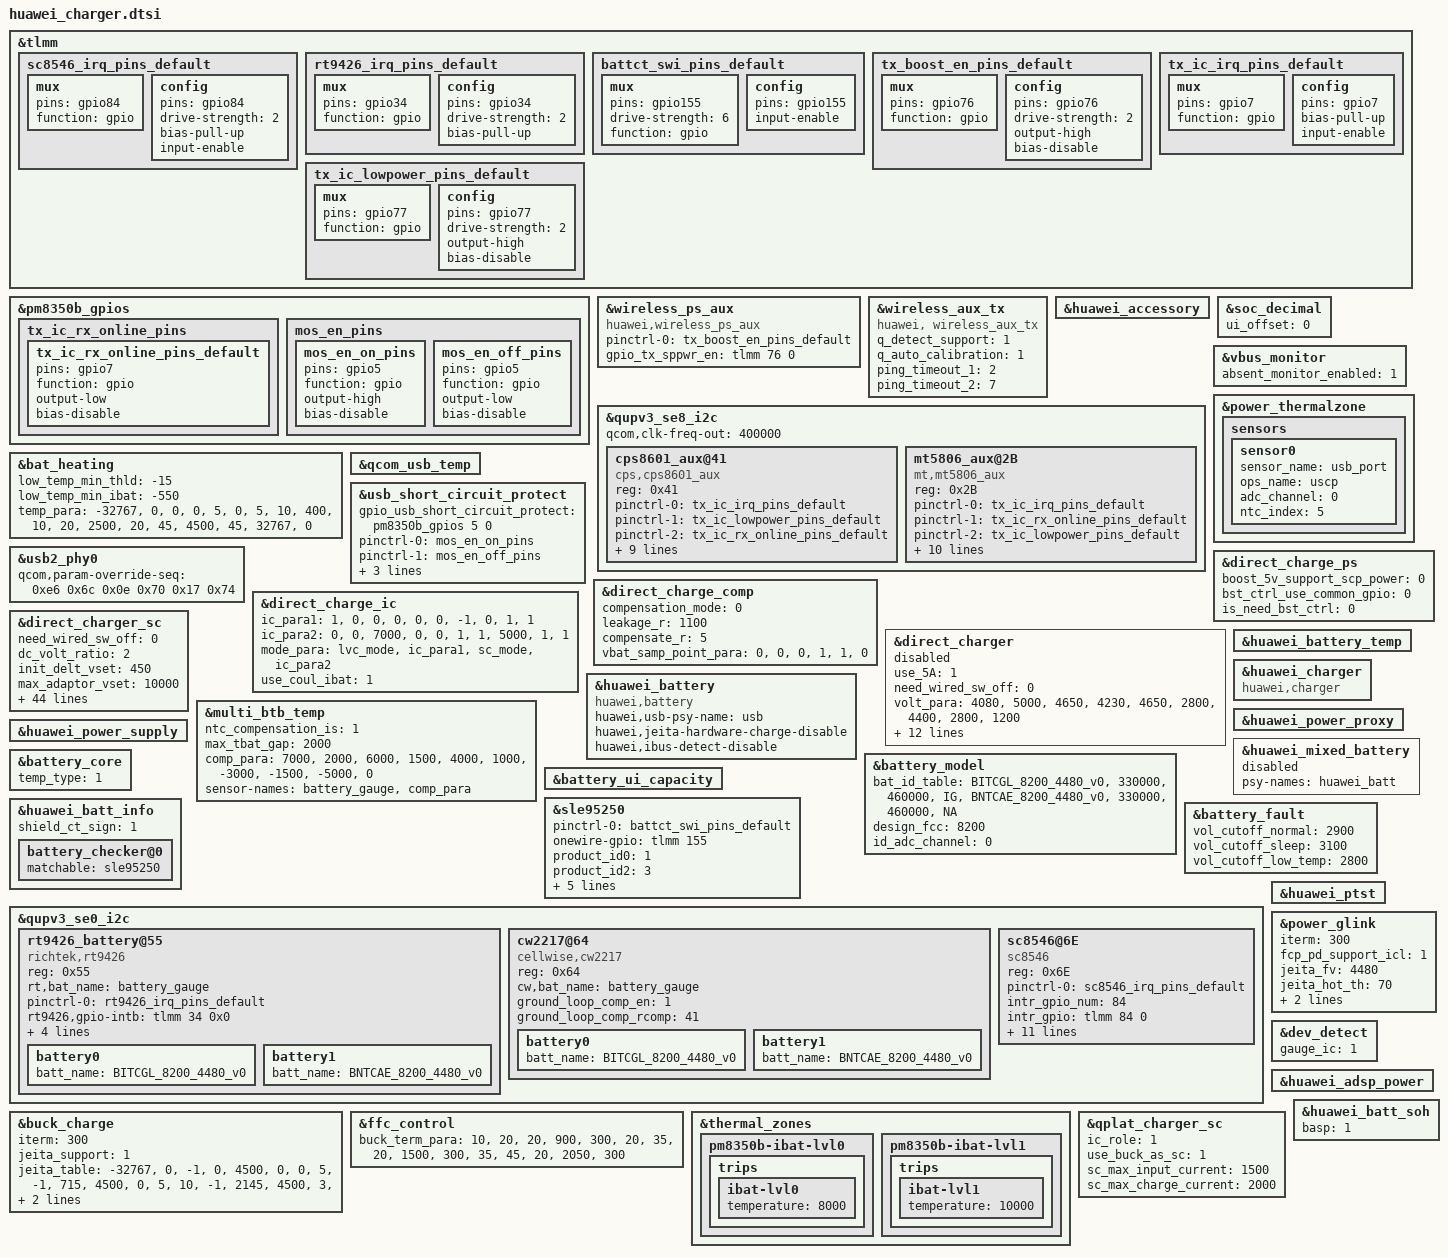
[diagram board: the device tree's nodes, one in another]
&tlmm {
	sc8546_irq_pins_default: sc8546_irq_pins_default {
		mux {
			pins = "gpio84";
			function = "gpio";
		};
		config {
			pins = "gpio84";
			drive-strength = <2>;
			bias-pull-up;
			input-enable;
		};
	};

	rt9426_irq_pins_default: rt9426_irq_pins_default {
		mux {
			pins = "gpio34";
			function = "gpio";
		};
		config {
			pins = "gpio34";
			drive-strength = <2>;
			bias-pull-up;
		};
	};

	battct_swi_pins_default: battct_swi_pins_default {
		mux {
			pins = "gpio155";
			drive-strength = <6>;
			function = "gpio";
		};
		config {
			pins = "gpio155";
			input-enable;
		};
	};

	tx_boost_en_pins_default: tx_boost_en_pins_default {
		mux {
			pins = "gpio76";
			function = "gpio";
		};
		config {
			pins = "gpio76";
			drive-strength = <2>;
			output-high;
			bias-disable;
		};
	};

	tx_ic_irq_pins_default: tx_ic_irq_pins_default {
		mux {
			pins = "gpio7";
			function = "gpio";
		};
		config {
			pins = "gpio7";
			bias-pull-up;
			input-enable;
		};
	};

	tx_ic_lowpower_pins_default: tx_ic_lowpower_pins_default {
		mux {
			pins = "gpio77";
			function = "gpio";
		};
		config {
			pins = "gpio77";
			drive-strength = <2>;
			output-high;
			bias-disable;
		};
	};
};

&pm8350b_gpios {
	tx_ic_rx_online_pins {
		tx_ic_rx_online_pins_default: tx_ic_rx_online_pins_default {
				pins = "gpio7";
				function = "gpio";
				output-low;
				bias-disable;
		};
	};
	mos_en_pins {
		mos_en_on_pins: mos_en_on_pins {
				pins = "gpio5";
				function = "gpio";
				output-high;
				bias-disable;
		};
		mos_en_off_pins: mos_en_off_pins {
				pins = "gpio5";
				function = "gpio";
				output-low;
				bias-disable;
		};
	};
};

&wireless_ps_aux {
	compatible = "huawei,wireless_ps_aux";
	pinctrl-names = "default";
	pinctrl-0 = <&tx_boost_en_pins_default>;
	gpio_tx_sppwr_en = <&tlmm 76 0>;
	status = "ok";
};

&wireless_aux_tx {
	compatible = "huawei, wireless_aux_tx";
	q_detect_support = <1>;
	q_auto_calibration = <1>;
	ping_timeout_1 = <2>;
	ping_timeout_2 = <7>;
	status = "ok";
};

&huawei_accessory {
	status = "ok";
};

&qupv3_se8_i2c {
	#address-cells = <1>;
	#size-cells = <0>;
	qcom,clk-freq-out = <400000>;
	status = "ok";

	cps8601_aux@41 {
		compatible = "cps,cps8601_aux";
		reg = <0x41>;
		pinctrl-names = "irq", "lowpower", "rx_online";
		pinctrl-0 = <&tx_ic_irq_pins_default>;
		pinctrl-1 = <&tx_ic_lowpower_pins_default>;
		pinctrl-2 = <&tx_ic_rx_online_pins_default>;
		interrupt-parent = <&tlmm>;
		interrupts = <7 0>;
		gpio_int = <&tlmm 7 0>;
		gpio_lowpower = <&tlmm 77 0>;
		gpio_rx_online = <&pm8350b_gpios 7 0>;
		tx_min_fop = /bits/ 16 <120>;
		tx_max_fop = /bits/ 16 <145>;
		tx_ploss_th0 = /bits/ 16 <2500>;
		tx_ploss_cnt = /bits/ 8 <5>;
		status = "ok";
	};

	mt5806_aux@2B {
                compatible = "mt,mt5806_aux";
                reg = <0x2B>;
                pinctrl-names = "irq", "lowpower", "rx_online";
                pinctrl-0 = <&tx_ic_irq_pins_default>;
                pinctrl-1 = <&tx_ic_rx_online_pins_default>;
                pinctrl-2 = <&tx_ic_lowpower_pins_default>;
                interrupt-parent = <&tlmm>;
                interrupts = <7 0>;
                gpio_int = <&tlmm 7 0>;
                gpio_lowpower = <&tlmm 77 0>;
                gpio_rx_online = <&pm8350b_gpios 7 0>;
                tx_ping_ocp_th = <1200>;
                tx_min_fop = /bits/ 16 <120>;
                tx_max_fop = /bits/ 16 <145>;
                tx_ploss_th0 = /bits/ 16 <2500>;
                tx_ploss_cnt = /bits/ 8 <5>;
                status = "ok";
        };
};

&bat_heating {
	low_temp_min_thld = "-15";
	low_temp_min_ibat = "-550";
	temp_para =
		"-32767", "0", "0",
		"0", "5", "0",
		"5", "10", "400",
		"10", "20", "2500",
		"20", "45", "4500",
		"45", "32767", "0";
	status = "ok";
};

&soc_decimal {
	ui_offset = <0>;
	status = "ok";
};

&vbus_monitor {
	status = "ok";
	absent_monitor_enabled = <1>;
};

&power_thermalzone {
	status = "ok";
	sensors{
		sensor0 {
			sensor_name = "usb_port";
			ops_name = "uscp";
			adc_channel = <0>;
			ntc_index = <5>;
		};
	};
};

&qcom_usb_temp {
	status = "ok";
};

&usb_short_circuit_protect {
	gpio_usb_short_circuit_protect = <&pm8350b_gpios 5 0>;
	pinctrl-names =  "mos_en_on", "mos_en_off";
	pinctrl-0 = <&mos_en_on_pins>;
	pinctrl-1 = <&mos_en_off_pins>;
	interval_switch_temp = <15>;
	use_pinctrl;
	open_mosfet_temp = <30>;
	status = "ok";
};

&usb2_phy0 {
	status = "ok";
	qcom,param-override-seq =
			<0xe6 0x6c     /* override_x0 */
			0x0e 0x70      /* override_x1 */
			0x17 0x74>;    /* override_x2 */
};

&direct_charge_ps {
	boost_5v_support_scp_power = <0>;
	bst_ctrl_use_common_gpio = <0>;
	is_need_bst_ctrl = <0>;
	status = "ok";
};

&direct_charge_comp {
	compensation_mode = <0>;
	leakage_r = <1100>;
	compensate_r = <5>;
	/* The vbat_samp_point_para table is used to find the comp relationship between chips */
	/* Calculate all compensation values of the same index */
	/* as the final compensation of the chip */
	/* Separately calculate positive and negative poles */
	/* ic_index  p_index  n_index */
	vbat_samp_point_para =
		"0", "0", "0",
		"1", "1", "0";
	status = "ok";
};

&direct_charge_ic {
	/* The IC_PARA table is used to find the relationship between chip and path */
	/* the chip's current passing capacity */
	/* and the sampling points of battery voltage and current */
	/* ic_index  path_index  max_ibat  ibat_sample_point  vbat_sample_point */
	ic_para1 =
		"1", "0", "0", "0", "0",
		"0", "-1", "0", "1", "1";
	ic_para2 =
		"0", "0", "7000", "0", "0",
		"1", "1", "5000", "1", "1";
	mode_para =
		"lvc_mode", "ic_para1",
		"sc_mode", "ic_para2";
	use_coul_ibat = <1>;
	status = "ok";
};

&direct_charger {
	use_5A = <1>;
	need_wired_sw_off = <0>;
	volt_para =
		"4080", "5000", "4650",
		"4230", "4650", "2800",
		"4400", "2800", "1200";
	vbat_comp_para =
		"default", "50", "0";
	compensate_r = <0>;
	cc_cable_detect_enable = <1>;
	full_path_res_max = <220>;
	scp_work_on_charger = <1>;
	standard_cable_full_path_res_max = <330>;
	first_cc_stage_timer_in_min = <5>;
	stage_need_to_jump = "1";
	low_temp_hysteresis = <5>;
	temp_para =
		"-32767", "10", "0",
		"10", "45", "5000",
		"45", "32767", "0";
	rt_test_para =
		"2000", "105"; /* rt_curr_th rt_test_time */
	status = "disabled";
};

&direct_charger_sc {
	need_wired_sw_off = <0>;
	dc_volt_ratio = <2>;
	init_delt_vset = <450>;
	max_adaptor_vset = <10000>;
	init_adapter_vset = <8800>;
	vol_err_th = <500>;
	adaptor_leakage_current_th = <600>;
	vstep = <20>;
	min_dc_bat_vol = <3450>;
	max_dc_bat_vol = <4380>;
	max_current_for_none_standard_cable = <6000>;
	adaptor_antifake_check_enable = <0>;
	adaptor_antifake_key_index = <2>;
	support_multi_ic = <1>;
	multi_ic_ibat_th = <5200>;
        curr_offset = <200>;
	second_resist_check_en = <1>;
	ui_max_pwr = <40000>;
	delta_err_10v2p25a = <150>;
	is_show_ico_first = <1>;
	volt_para =
		"4350", "8000", "7000",
		"4490", "7000", "2050";
	time_para =
		"1800", "7000",
		"900", "7500";
	bat_para =
		"default", "10", "45", "volt_para",
		"CAE", "10", "45", "volt_para",
		"CGL", "10", "45", "volt_para";
	vbat_comp_para =
		"default", "45", "0";
	vstep_para =
		"2000", "80";
	compensate_r = <0>;
	cc_cable_detect_enable = <1>;
	full_path_res_max = <450>;
	scp_work_on_charger = <1>;
	standard_cable_full_path_res_max = <450>;
	first_cc_stage_timer_in_min = <15>;
	stage_need_to_jump = "-1";
	low_temp_hysteresis = <5>;
	current_ratio =
		"3", "5", "35", "2", "-1",
		"3", "6", "35", "1", "8000",
		"0", "6", "35", "0", "0";
	vbat_error =
		"3", "120", "2", "-1",
		"3", "80", "1", "0";
	temp_para =
		"-32767", "10", "0",
		"10", "45", "8000",
		"45", "32767", "0";
	resist_para =
		"0", "260", "6000",
		"260", "450", "4000";
	std_resist_para =
		"0", "300", "0",
		"300", "450", "8000";
	second_resist_para =
		"0", "180", "0",
		"180", "450", "8000";
	ctc_second_resist_para =
		"0", "250", "0",
		"250", "450", "8000";
	rt_test_para =
		/* first:sc second:mainsc third:auxsc */
		"3000", "105",
		"3000", "105",
		"3000", "105";
	adapter_max_power_time_para =
		"3", "900", "7000",
		"7", "900", "7000",
		"8", "900", "7000",
		"17", "900", "7000",
		"19", "900", "7000";
	status = "ok";
};

&huawei_battery_temp {
	status = "ok";
};

&multi_btb_temp {
	status = "ok";
	ntc_compensation_is = <1>;
	max_tbat_gap = <2000>;
	comp_para =
		"7000", "2000",
		"6000", "1500",
		"4000", "1000",
		"-3000", "-1500",
		"-5000", "0";
	sensor-names =
		"battery_gauge", "comp_para";
};

&huawei_battery {
	compatible = "huawei,battery";
	status = "ok";
	huawei,usb-psy-name = "usb";
	huawei,jeita-hardware-charge-disable;
	huawei,ibus-detect-disable;
};

&huawei_charger {
	compatible = "huawei,charger";
	status = "ok";
};

&battery_model {
	bat_id_table =
		"BITCGL_8200_4480_v0", "330000", "460000", "IG",
		"BNTCAE_8200_4480_v0", "330000", "460000", "NA";
	design_fcc = <8200>;
	id_adc_channel = <0>; /* useless but necessary for Qcom, set 0 as default */
	status = "ok";
};

&huawei_power_proxy {
	status = "ok";
};

&huawei_power_supply {
	 status = "ok";
};

&huawei_mixed_battery {
	psy-names = "huawei_batt";
	status = "disabled";
};

&battery_core {
	temp_type = <1>;
	status = "ok";
};

&battery_ui_capacity {
	status = "ok";
};

&sle95250 {
	pinctrl-names = "default";
	pinctrl-0 = <&battct_swi_pins_default>;
	onewire-gpio = <&tlmm 155 0>;
	product_id0 = <1>;
	product_id2 = <3>;
	dip_check = <0>;
	gpio_swi = <155>;
	gpio_swi_drv = <2>;
	tau = /bits/ 8 <0xa>;
	tau_fastboot = <7>;
	status = "ok";
};

&huawei_batt_info {
	status = "ok";
	shield_ct_sign = <1>;
	battery_checker@0 {
		matchable = <&sle95250>;
		status = "ok";
	};
};

&battery_fault {
	vol_cutoff_normal = <2900>;
	vol_cutoff_sleep = <3100>;
	vol_cutoff_low_temp = <2800>;
	status = "ok";
};

&qupv3_se0_i2c {
	status = "ok";
	rt9426_battery@55{
		reg = <0x55>;
		compatible = "richtek,rt9426";
		rt,bat_name = "battery_gauge";
		pinctrl-names = "default";
		pinctrl-0 = <&rt9426_irq_pins_default>;
		rt9426,gpio-intb = <&tlmm 34 0x0>;
		need_reset_version = <9>;
		rt_config_ver = <17>;
		ground_loop_comp_en = <1>;
		ground_loop_comp_rcomp = <41>;
		status = "ok";
		battery0{
			batt_name = "BITCGL_8200_4480_v0";
			#include "../../../huawei_charger/rt9426_BITCGL_8200mAh_4V48_GOT_BT243.dtsi"
		};
		battery1{
			batt_name = "BNTCAE_8200_4480_v0";
			#include "../../../huawei_charger/rt9426_BNTCAE_8200mAh_4V48_GOT_BT243.dtsi"
		};
	};

	cw2217@64 {
		compatible = "cellwise,cw2217";
		reg = <0x64>;
		cw,bat_name = "battery_gauge";
		ground_loop_comp_en = <1>;
		ground_loop_comp_rcomp = <41>;
		status = "ok";
		battery0{
			batt_name = "BITCGL_8200_4480_v0";
			#include "../../../huawei_charger/cw2217_1mohm_BITCGL_8200mAh_4V48_GOT_BT243.dtsi"
		};
		battery1{
			batt_name = "BNTCAE_8200_4480_v0";
			#include "../../../huawei_charger/cw2217_1mohm_BNTCAE_8200mAh_4V48_GOT_BT243.dtsi"
		};
	};

	sc8546@6E {
		compatible = "sc8546";
		reg = <0x6E>;
		pinctrl-names = "default";
		pinctrl-0 = <&sc8546_irq_pins_default>;
		intr_gpio_num = <84>; /* direct defined GPIO num */
		intr_gpio = <&tlmm 84 0>;
		fcp_support = <1>;
		scp_support = <1>;
		ufcs_support = <1>;
		sense_r_actual = <20>;
		i2c_recovery = <1>;
		i2c_recovery_addr = <0x6F>;
		switching_frequency = <850>;
		switching_frequency_shift = <1>;
		sc_para =
			"default", "7000", "4800",
			"sc8546", "7000", "4800";
		ic_role = <0>;
		status = "ok";
	};

};

&huawei_ptst {
	status = "ok";
};

&buck_charge {
	iterm = <300>;
	jeita_support = <1>;
	jeita_table =
		"-32767", "0", "-1", "0", "4500", "0",
		"0", "5", "-1", "715", "4500", "0",
		"5", "10", "-1", "2145", "4500", "3",
		"10", "45", "-1", "3000", "4500", "3",
		"45", "50", "-1", "2502", "4100", "3",
		"50", "32767", "-1", "0", "4100", "0";
	status = "ok";
};

&power_glink {
	iterm = <300>;
	fcp_pd_support_icl = <1>;
	jeita_fv = <4480>;
	jeita_hot_th = <70>;
	adsp_jeita_table = <
		0 5 3000 4500
		5 10 3000 4500
		10 65 3000 4500
		65 70 3000 4100
	>;
};

&ffc_control {
	status = "ok";
	buck_term_para =
		"10", "20", "20", "900", "300",
		"20", "35", "20", "1500", "300",
		"35", "45", "20", "2050", "300";
};

&dev_detect {
	gauge_ic = <1>;
	status = "ok";
};

&thermal_zones {
	pm8350b-ibat-lvl0 {
		trips {
			ibat-lvl0 {
				temperature = <8000>;
			};
		};
	};

	pm8350b-ibat-lvl1 {
		trips {
			ibat-lvl1 {
				temperature = <10000>;
			};
		};
	};
};

&huawei_adsp_power {
	status = "ok";
};

&qplat_charger_sc {
	ic_role = <1>;
	use_buck_as_sc = <1>;
	sc_max_input_current = <1500>;
	sc_max_charge_current = <2000>;
	status = "ok";
};

&huawei_batt_soh {
	basp = <1>;
	status = "ok";
};
